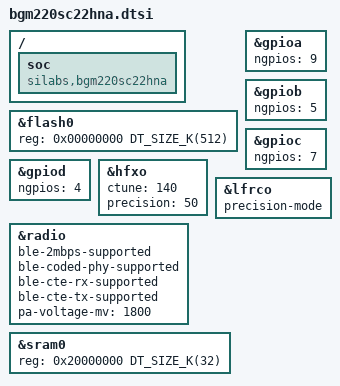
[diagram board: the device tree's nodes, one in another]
/*
 * Copyright (c) 2021 Sateesh Kotapati
 * Copyright (c) 2025 Silicon Laboratories Inc.
 * Copyright (c) 2025 Glassboard
 *
 * SPDX-License-Identifier: Apache-2.0
 */

#include <mem.h>
#include <silabs/xg22/bgm22.dtsi>

/ {
	soc {
		compatible = "silabs,bgm220sc22hna", "silabs,bgm22", "silabs,xg22", "silabs,efr32",
			     "simple-bus";
	};
};

&flash0 {
	reg = <0x00000000 DT_SIZE_K(512)>;
};

&gpioa {
	ngpios = <9>;
};

&gpiob {
	ngpios = <5>;
};

&gpioc {
	ngpios = <7>;
};

&gpiod {
	ngpios = <4>;
};

&hfxo {
	ctune = <140>;
	precision = <50>;
	status = "okay";
};

&lfrco {
	precision-mode;
};

&radio {
	ble-2mbps-supported;
	ble-coded-phy-supported;
	ble-cte-rx-supported;
	ble-cte-tx-supported;
	pa-voltage-mv = <1800>;
};

&sram0 {
	reg = <0x20000000 DT_SIZE_K(32)>;
};
